# HC32A4A8RITJ register map
File version: 1.0
CPU: CM4 r0p1, little endian, MPU, FPU, 4 interrupt priority bits
Registers are 32-bit, read-write, reset 0x0 unless marked. A register's access mark holds for its fields unless they carry their own. Offsets are from the block's base; [hi:lo] are bit positions; {n}, {i} and the like mark numbered series; 'fields as' and 'values as' point back to an identical list.

## SKE
Base 0x4000E000
0x00 CTRL
  [0] START
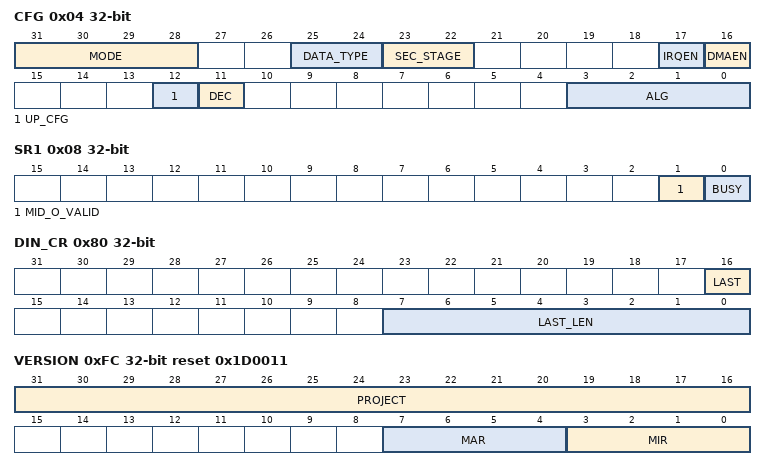
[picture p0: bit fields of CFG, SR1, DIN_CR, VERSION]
0x04 CFG
  [31:28] MODE, [25:24] DATA_TYPE, [23:22] SEC_STAGE, [17] IRQEN, [16] DMAEN, [12] UP_CFG, [11] DEC, [3:0] ALG
0x08 SR1
  [1] MID_O_VALID, [0] BUSY ro
0x0C SR2
  [0] CORE_DONE
{0xC+4i} KEY{i} wo (i=1..8)
0x60 AAD1
0x64 AAD2
0x68 CLEN1
0x6C CLEN2
{0x6C+4i} IV{i} (i=1..4)
0x80 DIN_CR
  [16] LAST, [7:0] LAST_LEN
{0x8C+4i} DIN{i} wo (i=1..4)
{0xAC+4i} DOUT{i} ro (i=1..4)
0xFC VERSION ro reset 0x1D0011
  [31:16] PROJECT, [7:4] MAR, [3:0] MIR
{0x19C+4i} MID_IV{i} (i=1..4)
{0x1AC+4i} MID_MAC{i} (i=1..4)
0x1C0 TOTAL_AAD1
0x1C4 TOTAL_AAD2
0x1C8 TOTAL_CLEN1
0x1CC TOTAL_CLEN2

## SMC
Base 0x88000000
0x00 STSR ro reset 0x1
  [0] STATUS
0x08 STCR0 wo
  [2] LPWIR
0x0C STCR1 wo
  [2] LPWOR
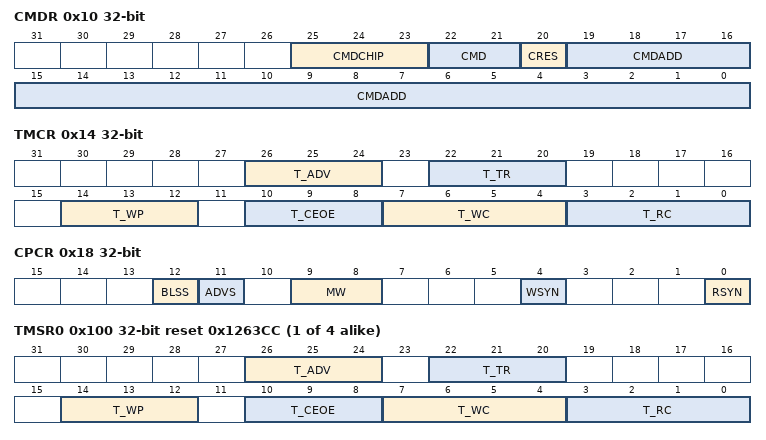
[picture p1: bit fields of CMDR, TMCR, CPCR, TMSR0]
0x10 CMDR wo
  [25:23] CMDCHIP, [22:21] CMD, [20] CRES, [19:0] CMDADD
0x14 TMCR wo
  [26:24] T_ADV, [22:20] T_TR, [14:12] T_WP, [10:8] T_CEOE, [7:4] T_WC, [3:0] T_RC
0x18 CPCR wo
  [12] BLSS, [11] ADVS, [9:8] MW, [4] WSYN, [0] RSYN
{0x100+0x20*i} TMSR{i} ro reset 0x1263CC (i=0..3)
  fields as TMCR
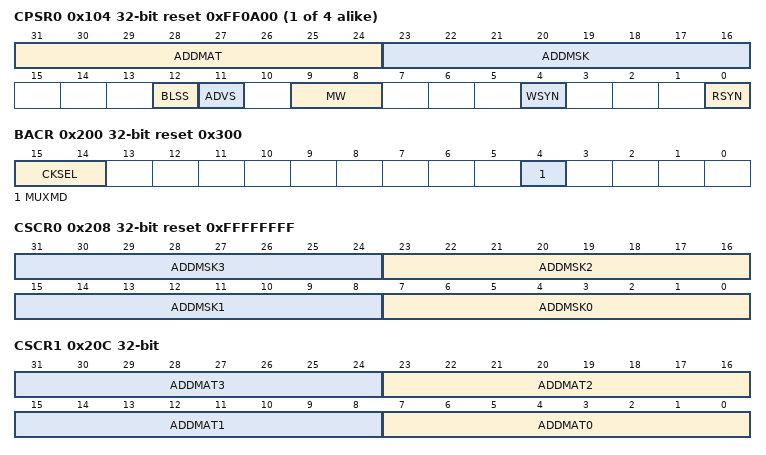
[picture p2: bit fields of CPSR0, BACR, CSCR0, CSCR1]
{0x104+0x20*i} CPSR{i} ro reset 0xFF0A00 (i=0..3)
  [31:24] ADDMAT, [23:16] ADDMSK, [12] BLSS, [11] ADVS, [9:8] MW, [4] WSYN, [0] RSYN
0x200 BACR reset 0x300
  [15:14] CKSEL, [4] MUXMD
0x208 CSCR0 reset 0xFFFFFFFF
  [8n+7:8n] ADDMSK{n} (n=0..3)
0x20C CSCR1
  [8n+7:8n] ADDMAT{n} (n=0..3)

## SPI1 — desc SPI
Base 0x4001C000
Same registers: SPI2 0x4001C400, SPI3 0x4001C800, SPI4 0x40020000, SPI5 0x40020400, SPI6 0x40020800
0x00 DR
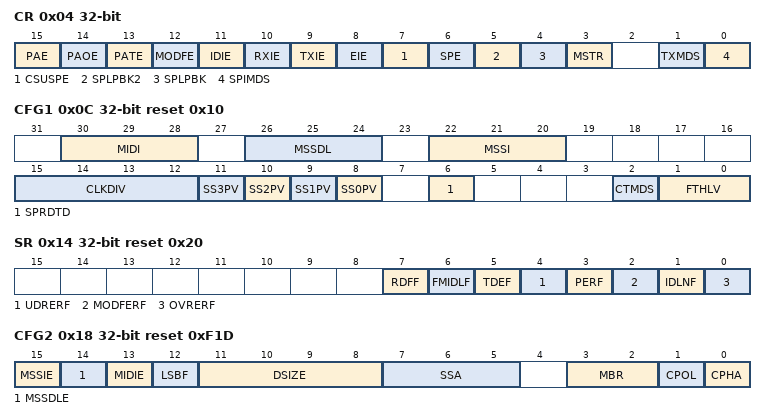
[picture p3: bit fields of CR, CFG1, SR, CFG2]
0x04 CR
  [15] PAE, [14] PAOE, [13] PATE, [12] MODFE, [11] IDIE, [10] RXIE, [9] TXIE, [8] EIE, [7] CSUSPE, [6] SPE, [5] SPLPBK2, [4] SPLPBK, [3] MSTR, [1] TXMDS, [0] SPIMDS
0x0C CFG1 reset 0x10
  [30:28] MIDI, [26:24] MSSDL, [22:20] MSSI, [15:12] CLKDIV, [n+8] SS{n}PV (n=0..3), [6] SPRDTD, [2] CTMDS, [1:0] FTHLV
0x14 SR reset 0x20
  [7] RDFF ro, [6] FMIDLF ro, [5] TDEF ro, [4] UDRERF, [3] PERF, [2] MODFERF, [1] IDLNF ro, [0] OVRERF
0x18 CFG2 reset 0xF1D
  [15] MSSIE, [14] MSSDLE, [13] MIDIE, [12] LSBF, [11:8] DSIZE, [7:5] SSA, [3:2] MBR, [1] CPOL, [0] CPHA

## SRAMC
Base 0x40050800
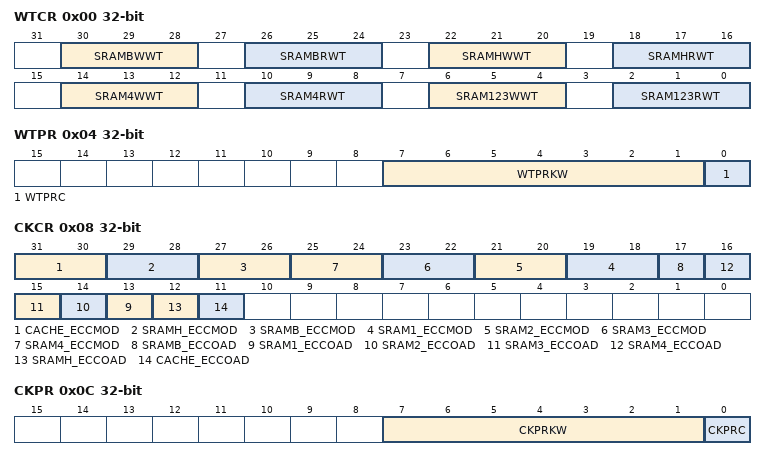
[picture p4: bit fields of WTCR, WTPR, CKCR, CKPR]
0x00 WTCR
  [30:28] SRAMBWWT, [26:24] SRAMBRWT, [22:20] SRAMHWWT, [18:16] SRAMHRWT, [14:12] SRAM4WWT, [10:8] SRAM4RWT, [6:4] SRAM123WWT, [2:0] SRAM123RWT
0x04 WTPR
  [7:1] WTPRKW, [0] WTPRC
0x08 CKCR
  [31:30] CACHE_ECCMOD, [29:28] SRAMH_ECCMOD, [27:26] SRAMB_ECCMOD, [2n+17:2n+16] SRAM{n}_ECCMOD (n=1..4), [17] SRAMB_ECCOAD, [n+12] SRAM{n}_ECCOAD (n=1..4), [12] SRAMH_ECCOAD, [11] CACHE_ECCOAD
0x0C CKPR
  [7:1] CKPRKW, [0] CKPRC
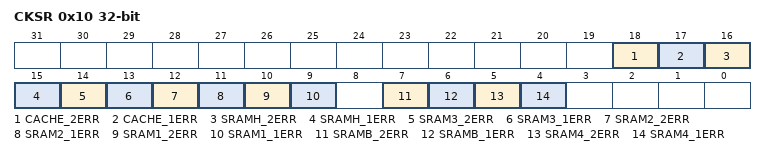
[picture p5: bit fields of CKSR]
0x10 CKSR
  [18] CACHE_2ERR, [17] CACHE_1ERR, [16] SRAMH_2ERR, [15] SRAMH_1ERR, [14] SRAM3_2ERR, [13] SRAM3_1ERR, [12] SRAM2_2ERR, [11] SRAM2_1ERR, [10] SRAM1_2ERR, [9] SRAM1_1ERR, [7] SRAMB_2ERR, [6] SRAMB_1ERR, [5] SRAM4_2ERR, [4] SRAM4_1ERR
{0x4+0x10*i} SRAM{i}_EIEN (i=1..4)
  [0] EIEN
{0x8+0x10*i} SRAM{i}_EIBIT0 (i=1..4)
{0xC+0x10*i} SRAM{i}_EIBIT1 (i=1..4)
  [6:0] EIBIT
{0x10+0x10*i} SRAM{i}_ECCERRADDR (i=1..3)
  [16:0] ECCERRADDR
0x50 SRAM4_ECCERRADDR
  [14:0] ECCERRADDR
0x54 SRAMH_EIEN
  [0] EIEN
0x58 SRAMH_EIBIT0
0x5C SRAMH_EIBIT1
  [6:0] EIBIT
0x60 SRAMH_ECCERRADDR
  [16:0] ECCERRADDR
0x64 SRAMB_EIEN
  [0] EIEN
0x68 SRAMB_EIBIT0
0x6C SRAMB_EIBIT1
  [6:0] EIBIT
0x70 SRAMB_ECCERRADDR
  [11:0] ECCERRADDR
0x74 CACHE_EIEN
  [0] EIEN
{0x78+4i} CACHE_EIBIT{i} (i=0..3)
0x88 CACHE_EIBIT4
  [8:0] EIBIT
0x8C CACHE_ECCERRADDR
  [12:0] ECCERRADDR

## SWDT
Base 0x40049400
Same registers: WDT 0x40049000
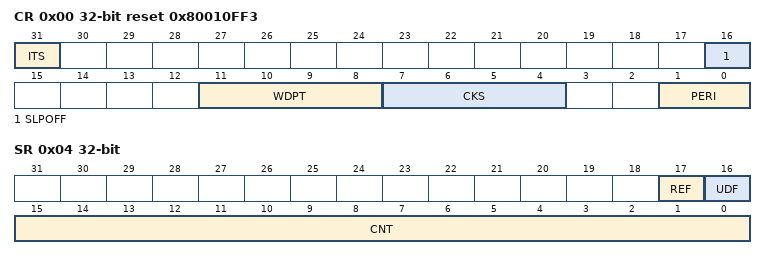
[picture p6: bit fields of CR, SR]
0x00 CR reset 0x80010FF3
  [31] ITS, [16] SLPOFF, [11:8] WDPT, [7:4] CKS, [1:0] PERI
0x04 SR
  [17] REF, [16] UDF, [15:0] CNT ro
0x08 RR
  [15:0] RF

## TMR01 — desc TMR0
Base 0x40024000
Same registers: TMR02 0x40024400, TMR03 0x40029000, TMR04 0x40029400, TMR05 0x40029800
0x00 CNTAR
  [15:0] CNTA
0x04 CNTBR
  [15:0] CNTB
0x08 CMPAR reset 0xFFFF
  [15:0] CMPA
0x0C CMPBR reset 0xFFFF
  [15:0] CMPB
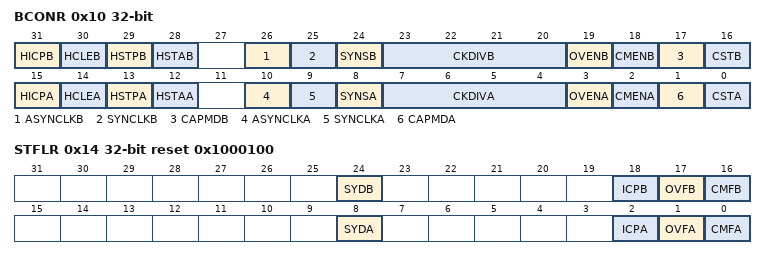
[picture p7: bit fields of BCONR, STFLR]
0x10 BCONR
  [31] HICPB, [30] HCLEB, [29] HSTPB, [28] HSTAB, [26] ASYNCLKB, [25] SYNCLKB, [24] SYNSB, [23:20] CKDIVB, [19] OVENB, [18] CMENB, [17] CAPMDB, [16] CSTB, [15] HICPA, [14] HCLEA, [13] HSTPA, [12] HSTAA, [10] ASYNCLKA, [9] SYNCLKA, [8] SYNSA, [7:4] CKDIVA, [3] OVENA, [2] CMENA, [1] CAPMDA, [0] CSTA
0x14 STFLR reset 0x1000100
  [24] SYDB ro, [18] ICPB, [17] OVFB, [16] CMFB, [8] SYDA ro, [2] ICPA, [1] OVFA, [0] CMFA
